AUTOSAR XML (schema 4-2-2)
package /ASW_COM_STD_Package
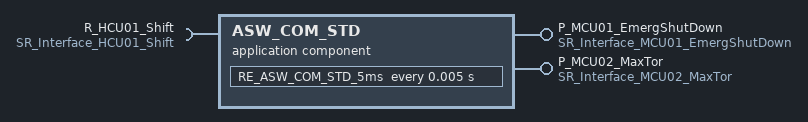
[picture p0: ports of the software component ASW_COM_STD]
  application sw component type ASW_COM_STD
    provide port P_MCU01_EmergShutDown: provided-interface=SR_Interface_MCU01_EmergShutDown
    provide port P_MCU02_MaxTor: provided-interface=SR_Interface_MCU02_MaxTor
    require port R_HCU01_Shift: nonqueued-receiver-com-spec{data-element=HCU01_Shift, alive-timeout=0.3, init-value=0}, required-interface=SR_Interface_HCU01_Shift
    behavior IB_ASW_COM_STD
      timing event TE_ASW_COM_STD_5ms: start-on-event=RE_ASW_COM_STD_5ms, period=0.005
      runnable RE_ASW_COM_STD_5ms
        data-read-access:
          access RA_HCU01_Shift: accessed-variable=R_HCU01_Shift.HCU01_Shift
        data-write-access:
          access WA_MCU01_EmergShutDown: accessed-variable=P_MCU01_EmergShutDown.MCU01_EmergShutDown
          access WA_MCU02_MaxTor: accessed-variable=P_MCU02_MaxTor.MCU02_MaxTor
